# UPD70F3508 register map
Vendor: Renesas; Series: V850E2/Px4; File version: 1.0
CPU: other r0p0, little endian, no MPU, FPU, 4 interrupt priority bits
Registers are 8-bit, read-write, reset 0x0 unless marked. A register's access mark holds for its fields unless they carry their own. Offsets are from the block's base; [hi:lo] are bit positions; lines under a group give offsets from that group; {n}, {i} and the like mark numbered series.

## PORT_CFG — Port 0 electrical configuration registers (merged: PORT0_CFG, PORT1_CFG, PORT2_CFG, PORT3_CFG, PORT4_CFG, PORT5_CFG, PORT6_CFG, PORT7_CFG, PORT8_CFG)
Base 0xFF404000
0x00 PIBC0 16-bit — Port 0 input buffer control register
  [15:0] PIBC0_15_0 — Input buffer enable: 0=disabled, 1=enabled
{0x0+4i} PIBC{i} 16-bit (i=1..8) — Port {i} input buffer control register
0x100 PBDC0 16-bit — Port 0 bi-direction control register
  [15:0] PBDC0_15_0 — Bi-directional mode: 0=disabled, 1=enabled (forces pin level readable)
0x104 PBDC1 16-bit — Port 1 bi-direction control register
{0x100+4i} PBDC{i} 16-bit (i=3..6) — Port {i} bi-direction control register
0x200 PIPC0 16-bit — Port 0 IP control register (I/O direction control)
  [15:0] PIPC0_15_0 — I/O control: 0=software (PM), 1=peripheral (direct)
{0x200+4i} PIPC{i} 16-bit (i=1..7) — Port {i} IP control register
0x300 PU0 16-bit — Port 0 pull-up option register
  [15:0] PU0_15_0 — Pull-up resistor: 0=disconnected, 1=connected
{0x300+4i} PU{i} 16-bit (i=1..8) — Port {i} pull-up option register
0x508 PODC2 32-bit — Port 2 open drain control register (protected write)
  [31:0] PODC2_31_0 — Output buffer: 0=push-pull, 1=open-drain
0x50C PODC3 32-bit — Port 3 open drain control register (protected write)
0x618 PDSC6 32-bit — Port 6 drive strength control register (protected write; 0=25MHz, 1=40MHz per bit)
  [31:0] PDSC6_31_0 — Drive strength per bit: 0=low (25 MHz), 1=high (40 MHz)
0x718 PIS6 16-bit — Port 6 input buffer selection register (0=Schmitt, 1=CMOS characteristics)
  [15:0] PIS6_15_0 — Input buffer type: 0=Schmitt trigger, 1=CMOS
0xB08 PPROTS2 ro — Port 2 protection status register
  [0] PPROTSn_0 — Protection error: 0=none, 1=write-sequence error
0xB0C PPROTS3 ro — Port 3 protection status register
  [0] PPROTSn_0 — Protection error flag
0xB18 PPROTS6 ro — Port 6 protection status register
  [0] PPROTSn_0 — Protection error flag
0xC08 PPCMD2 wo — Port 2 register protection command register
0xC0C PPCMD3 wo — Port 3 register protection command register
0xC18 PPCMD6 wo — Port 6 register protection command register

## DNF — Digital noise filter control registers (n=0..36, Table 2-58/2-59/2-61)
Base 0xFF410000
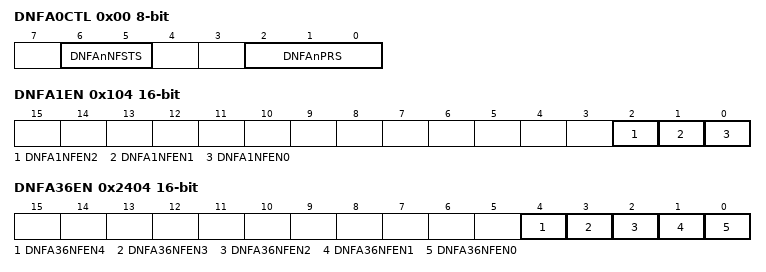
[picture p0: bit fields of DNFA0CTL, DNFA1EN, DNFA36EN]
0x00 DNFA0CTL — DNF group 0 (NMI) control register
  [6:5] DNFAnNFSTS — Number of same-level samples for validation [6:5]
  [2:0] DNFAnPRS — Sampling clock prescaler [2:0]
0x04 DNFA0EN 16-bit — DNF group 0 (NMI) enable register
  [0] DNFA0NFEN0 — NMI noise cancellation enable
0x100 DNFA1CTL — DNF group 1 (INTP0/1/2) control register
0x104 DNFA1EN 16-bit — DNF group 1 (INTP0/1/2) enable register
  [2] DNFA1NFEN2 — INTP2 noise cancellation enable
  [1] DNFA1NFEN1 — INTP1 noise cancellation enable
  [0] DNFA1NFEN0 — INTP0 noise cancellation enable
0x200 DNFA2CTL — DNF group 2 (INTP3/4/5) control register
0x204 DNFA2EN 16-bit — DNF group 2 (INTP3/4/5) enable register
0x300 DNFA3CTL — DNF group 3 (INTP6..10) control register
0x304 DNFA3EN 16-bit — DNF group 3 (INTP6..10) enable register
{0x0+0x100*i} DNFA{i}CTL (i=4..11) — DNF group {i} (TAUA0I{2i-8}/{2i-7}) control register
{0x4+0x100*i} DNFA{i}EN 16-bit (i=4..35) — DNF group {i} enable register
{0x0+0x100*i} DNFA{i}CTL (i=12..19) — DNF group {i} (TAUA1I{2i-24}/{2i-23}) control register
{0x0+0x100*i} DNFA{i}CTL (i=20..23) — DNF group {i} (TAUJ0I{i-20}) control register
{0x0+0x100*i} DNFA{i}CTL (i=24..27) — DNF group {i} (TAUJ1I{i-24}) control register
0x1C00 DNFA28CTL — DNF group 28 (TSG20PTSI0/1, ENCA0E0/1) control register
0x1D00 DNFA29CTL — DNF group 29 (TSG20PTSI2/ENCA0EC) control register
0x1E00 DNFA30CTL — DNF group 30 (TSG20CLKI) control register
0x1F00 DNFA31CTL — DNF group 31 (TSG21PTSI0/1, ENCA1E0/1) control register
0x2000 DNFA32CTL — DNF group 32 (TSG21PTSI2/ENCA1EC) control register
0x2100 DNFA33CTL — DNF group 33 (TSG21CLKI) control register
0x2200 DNFA34CTL — DNF group 34 (ENCA0I0/1) control register
0x2300 DNFA35CTL — DNF group 35 (ENCA1I0/1) control register
0x2400 DNFA36CTL — DNF group 36 (CSIG0/1/2RYI, CSIH0/1RYI) control register
0x2404 DNFA36EN 16-bit — DNF group 36 enable register
  [4] DNFA36NFEN4 — CSIG2RYI noise cancellation enable
  [3] DNFA36NFEN3 — CSIG1RYI noise cancellation enable
  [2] DNFA36NFEN2 — CSIG0RYI noise cancellation enable
  [1] DNFA36NFEN1 — CSIH1RYI noise cancellation enable
  [0] DNFA36NFEN0 — CSIH0RYI noise cancellation enable
